VERSION ""

NS_ :

BS_:

BU_: GNSS_Receiver
VAL_TABLE_ TIM_AuthErrorCode 39 "LwAPossibleBitMismatch" 38 "AuthenticationAbortedDueToGeneralPeerError" 37 "AuthenticationAbortedByPeerDueToError" 36 "ChallengeDataCorrupt" 35 "InvalidChallengeLength" 34 "FunctionFacilityNotCertified" 33 "RequestNotAllowed" 32 "Reserved_0x20" 31 "AuthenticationTimeout" 30 "CertificateTypeInvalid" 29 "DeviceCertificateRevoked" 28 "ManufacturerSeriesCertificateRevoked" 27 "ManufacturerCertificateRevoked" 26 "LabCertificateRevoked" 25 "RootCertificateRevoked" 24 "CertificateTypeMismatch" 23 "CertificateChainInvalid" 22 "ECU_CCID_Mismatch" 21 "NAME_Mismatch" 20 "ECC_PublicKeyValidationFailed" 19 "UnexpectedRestartAuthenticationBitSet" 18 "AuthenticationStatusInvalid" 17 "AuthenticationTypeNotSupported" 16 "AuthenticationStatusLost" 15 "DeviceCertificateDataCorrupt" 14 "ManufacturerSeriesCertificateDataCorrupt" 13 "ManufacturerCertificateDataCorrupt" 12 "TestLabCertificateDataCorrupt" 11 "RootCertificateDataCorrupt" 10 "InternalError" 9 "ChallengesDontMatch" 8 "DeviceCertificateSignatureInvalid" 7 "ManufacturerSeriesCertificateSignatureInvalid" 6 "ManufacturerCertificateSignatureInvalid" 5 "LabCertificateSignatureInvalid" 4 "RootCertificateSignatureInvalid" 3 "NotAuthenticationServerOrClient" 2 "CertificateFormatNotSupported" 1 "ParticipantBusy" 0 "NoError" ;
VAL_TABLE_ TIM_CertificateType 255 "NotAvailable" 6 "CRLCertificate" 5 "CRLSigningCertificate" 4 "DeviceCertificate" 3 "ManufacturerSeriesCertificate" 2 "ManufacturerCertificate" 1 "TestlabCertificate" 0 "AEFRootCertificate" ;
VAL_TABLE_ NetworkInterconnUnitParametrics 16 "NetworkInterconnectionUnitType" 15 "NumberOfPorts" 14 "UptimeSinceLastPowerOnReset " 13 "AverageNumOfMsgsFilteredPerSec" 12 "AverageNumOfMsgsForwardedPerSec" 11 "AverageNumOfMsgsReceivedPerSec" 10 "NumOfMsgsWithExcessTransitDelayTime " 9 "NumOfMsgsLostDueToBufferOverflow " 8 "AverageTransitDelayTime" 7 "MaxTransitDelayTime" 6 "MaxNumOfMsgsFilteredPerSec" 5 "MaxNumOfMsgsForwardedPerSec" 4 "MaxNumOfMsgsReceivedPerSec" 3 "NumberOfFilterDatabaseEntries" 2 "MaxFilterDatabaseSize" 1 "BufferSize" 0 "RequestAllParameters" ;
VAL_TABLE_ FMI 0 "Above normal (most severe)" 1 "Below normal (most severe)" 2 "Data erratic" 3 "Voltage above normal" 4 "Voltage below normal" 5 "Current below normal" 6 "Current above normal" 7 "Mechanical system not responding" 8 "Abnormal frequency" 9 "Abnormal update rate" 10 "Abnormal rate of change" 11 "Root cause not known" 12 "Bad intelligent device" 13 "Out of calibration" 14 "Special intstructions" 15 "Above normal (least severe)" 16 "Above normal (moderately severe)" 17 "Below normal (least severe)" 18 "Below normal (moderately severe)" 19 "Received network data in error" 31 "Condition exists" 20 "Data drifted high" 21 "Data drifted low" ;

BO_ 3221225472 VECTOR__INDEPENDENT_SIG_MSG: 0 Vector__XXX
 SG_ ClientAuthenticationSubStatus : 0|8@1- (1,0) [0|255] "" Vector__XXX
 SG_ ServerAuthenticationSubStatus : 0|8@1- (1,0) [0|255] "" Vector__XXX

BO_ 2566845438 VP1: 8 Vector__XXX
 SG_ Longitude : 32|32@1+ (1E-07,-210) [-210|211.1081215] "deg" Vector__XXX
 SG_ Latitude : 0|32@1+ (1E-07,-210) [-210|211.1081215] "deg" Vector__XXX

BO_ 2565537534 RQST: 3 Vector__XXX
 SG_ ParameterGroupNumber : 0|24@1+ (1,0) [0|16777215] "" Vector__XXX

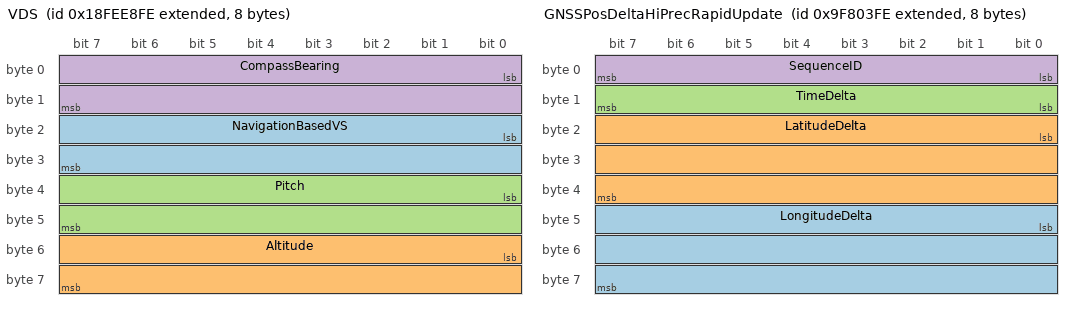
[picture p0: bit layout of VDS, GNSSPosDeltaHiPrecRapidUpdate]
BO_ 2566842622 VDS: 8 Vector__XXX
 SG_ NavigationBasedVS : 16|16@1+ (0.00390625,0) [0|250.99609375] "km/h" Vector__XXX
 SG_ Altitude : 48|16@1+ (0.125,-2500) [-2500|5531.875] "m" Vector__XXX
 SG_ Pitch : 32|16@1+ (0.0078125,-200) [-200|301.9921875] "deg" Vector__XXX
 SG_ CompassBearing : 0|16@1+ (0.0078125,0) [0|501.9921875] "deg" Vector__XXX

BO_ 2314732542 GNSSPosDeltaHiPrecRapidUpdate: 8 Vector__XXX
 SG_ LongitudeDelta : 40|24@1- (10,0) [0|0] "µsec" Vector__XXX
 SG_ LatitudeDelta : 16|24@1- (10,0) [0|0] "µsec" Vector__XXX
 SG_ TimeDelta : 8|8@1+ (5,0) [0|0] "ms" Vector__XXX
 SG_ SequenceID : 0|8@1+ (1,0) [0|0] "" Vector__XXX

BO_ 2314732030 GNSSPositionRapidUpdate: 8 Vector__XXX
 SG_ Longitude : 32|32@1- (1E-07,0) [-180|180] "deg" Vector__XXX
 SG_ Latitude : 0|32@1- (1E-07,0) [-90|90] "deg" Vector__XXX

BO_ 2381841918 GNSSPositionData: 47 Vector__XXX
 SG_ Reserved : 258|6@1+ (1,0) [0|0] "" Vector__XXX
 SG_ RefrenceStationType5 : 472|4@1+ (1,0) [0|15] "" Vector__XXX
 SG_ ReferenceStationID5 : 476|12@1+ (1,0) [0|4095] "" Vector__XXX
 SG_ AgeOfDGNSSCorrections5 : 488|16@1+ (0.01,0) [0|655.32] "sec" Vector__XXX
 SG_ RefrenceStationType4 : 440|4@1+ (1,0) [0|15] "" Vector__XXX
 SG_ ReferenceStationID4 : 444|12@1+ (1,0) [0|4095] "" Vector__XXX
 SG_ AgeOfDGNSSCorrections4 : 456|16@1+ (0.01,0) [0|655.32] "sec" Vector__XXX
 SG_ RefrenceStationType3 : 408|4@1+ (1,0) [0|15] "" Vector__XXX
 SG_ ReferenceStationID3 : 412|12@1+ (1,0) [0|4095] "" Vector__XXX
 SG_ AgeOfDGNSSCorrections3 : 424|16@1+ (0.01,0) [0|655.32] "sec" Vector__XXX
 SG_ RefrenceStationType2 : 376|4@1+ (1,0) [0|15] "" Vector__XXX
 SG_ ReferenceStationID2 : 380|12@1+ (1,0) [0|4095] "" Vector__XXX
 SG_ AgeOfDGNSSCorrections2 : 392|16@1+ (0.01,0) [0|655.32] "sec" Vector__XXX
 SG_ AgeOfDGNSSCorrections1 : 360|16@1+ (0.01,0) [0|655.32] "sec" Vector__XXX
 SG_ ReferenceStationID1 : 348|12@1+ (1,0) [0|4095] "" Vector__XXX
 SG_ RefrenceStationType1 : 344|4@1+ (1,0) [0|15] "" Vector__XXX
 SG_ NumberOfReferenceStations : 336|8@1+ (1,0) [0|252] "" Vector__XXX
 SG_ GeoidalSeparation : 304|32@1- (0.01,0) [-21470000|21470000] "m" Vector__XXX
 SG_ PDOP : 288|16@1- (0.01,0) [-327.64|327.64] "" Vector__XXX
 SG_ HDOP : 272|16@1- (0.01,0) [-327.64|327.64] "" Vector__XXX
 SG_ NumberOfSVs : 264|8@1+ (1,0) [0|252] "" Vector__XXX
 SG_ GNSSIntegrity : 256|2@1+ (1,0) [0|3] "" Vector__XXX
 SG_ GNSSMethod : 252|4@1+ (1,0) [0|15] "" Vector__XXX
 SG_ TypeOfSystem : 248|4@1+ (1,0) [0|4] "" Vector__XXX
 SG_ Altitude : 184|64@1- (1E-06,0) [-9223372036854.78|9223372036854.78] "m" Vector__XXX
 SG_ Longitude : 120|64@1- (1E-16,0) [-180|180] "deg" Vector__XXX
 SG_ Latitude : 56|64@1- (1E-16,0) [-90|90] "deg" Vector__XXX
 SG_ PositionTime : 24|32@1+ (0.0001,0) [0|86401] "s" Vector__XXX
 SG_ PositionDate : 8|16@1+ (1,0) [0|65532] "day" Vector__XXX
 SG_ SequenceID : 0|8@1+ (1,0) [0|255] "" Vector__XXX

BO_ 2565799678 AC: 8 GNSS_Receiver
 SG_ ReservedBit : 48|1@1+ (1,0) [0|0] "" Vector__XXX
 SG_ ArbitraryAddressCapable : 63|1@1+ (1,0) [0|1] "" Vector__XXX
 SG_ IndustryGroup M : 60|3@1+ (1,0) [0|7] "" Vector__XXX
 SG_ VehicleSystemInstance : 56|4@1+ (1,0) [0|15] "" Vector__XXX
 SG_ VehicleSystem m0 : 49|7@1+ (1,0) [0|127] "" Vector__XXX
 SG_ VehicleSystem5 m5 : 49|7@1+ (1,0) [0|127] "" Vector__XXX
 SG_ VehicleSystem4 m4 : 49|7@1+ (1,0) [0|127] "" Vector__XXX
 SG_ VehicleSystem3 m3 : 49|7@1+ (1,0) [0|127] "" Vector__XXX
 SG_ VehicleSystem2 m2 : 49|7@1+ (1,0) [0|127] "" Vector__XXX
 SG_ VehicleSystem1 m1 : 49|7@1+ (1,0) [0|127] "" Vector__XXX
 SG_ Function : 40|8@1+ (1,0) [0|255] "" Vector__XXX
 SG_ FunctionInstance : 35|5@1+ (1,0) [0|31] "" Vector__XXX
 SG_ ECUInstance : 32|3@1+ (1,0) [0|7] "" Vector__XXX
 SG_ ManufacturerCode : 21|11@1+ (1,0) [0|2047] "" Vector__XXX
 SG_ IdentityNumber : 0|21@1+ (1,0) [0|2097152] "" Vector__XXX

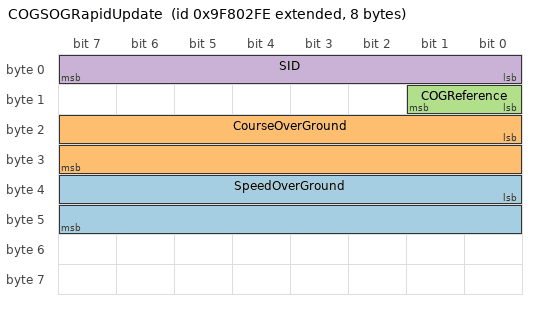
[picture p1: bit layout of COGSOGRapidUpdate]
BO_ 2314732286 COGSOGRapidUpdate: 8 Vector__XXX
 SG_ SpeedOverGround : 32|16@1+ (0.01,0) [0|655.32] "m/s" Vector__XXX
 SG_ CourseOverGround : 16|16@1+ (0.0001,0) [0|6.28318] "rad" Vector__XXX
 SG_ COGReference : 8|2@1+ (1,0) [0|3] "" Vector__XXX
 SG_ SID : 0|8@1+ (1,0) [0|252] "" Vector__XXX

CM_ BO_ 3221225472 "This is a message for not used signals, created by Vector CANdb++ DBC OLE DB Provider.";
CM_ SG_ 3221225472 ClientAuthenticationSubStatus "Sub-status of message Auth_ClientAuthenticationStatus (not mapped to AUTH21 because signals for every bit are used)";
CM_ SG_ 3221225472 ServerAuthenticationSubStatus "Sub-status of message Auth_ServerAuthenticationStatus (not mapped to AUTH12 because signals for every bit are used)";
CM_ BO_ 2566845438 "Vehicle Position 1";
CM_ SG_ 2566845438 Longitude "Longitude position of the vehicle.

Negative values are West and positive value are East.";
CM_ SG_ 2566845438 Latitude "Latitude position of the vehicle.

Negative values are South and positive values are North.";
CM_ BO_ 2565537534 "Request";
CM_ SG_ 2565537534 ParameterGroupNumber "PGN which is requested by the Request message";
CM_ BO_ 2566842622 "Vehicle Direction/Speed";
CM_ SG_ 2566842622 NavigationBasedVS "Speed of the vehicle as calculated from a device such as a Global Positioning System (GPS).";
CM_ SG_ 2566842622 Altitude "Altitude of the vehicle referenced to sea level at standard atmospheric pressure and temperature.";
CM_ SG_ 2566842622 Pitch "Pitch (rotation about the y-axis) of the vehicle as calculated by the navigation device(s).  The pitch angle for an angle of ascent is reported with a positive value. This parameter is defined according to a Z-Down axis system and the sign of the ...";
CM_ SG_ 2566842622 CompassBearing "Present compass bearing of vehicle.";
CM_ BO_ 2314732542 "This PGN is intended for applications where very high precision and very fast update rates are needed for position data 
and only has meaning when it is associated (via the Sequence ID field) with another PGN.";
CM_ SG_ 2314732542 SequenceID "An upward counting number used to tie related information together between different PGNs.";
CM_ BO_ 2314732030 "This PGN provides latitude and longitude referenced to WGS84";
CM_ BO_ 2381841918 "This PGN conveys a comprehensive set of Global Navigation Satellite System (GNSS) parameters, including position 
information
";
CM_ SG_ 2381841918 ReferenceStationID5 "Reference Station ID";
CM_ SG_ 2381841918 AgeOfDGNSSCorrections5 "Age of Differential corrections";
CM_ SG_ 2381841918 ReferenceStationID4 "Reference Station ID";
CM_ SG_ 2381841918 AgeOfDGNSSCorrections4 "Age of Differential corrections";
CM_ SG_ 2381841918 ReferenceStationID3 "Reference Station ID";
CM_ SG_ 2381841918 AgeOfDGNSSCorrections3 "Age of Differential corrections";
CM_ SG_ 2381841918 ReferenceStationID2 "Reference Station ID";
CM_ SG_ 2381841918 AgeOfDGNSSCorrections2 "Age of Differential corrections";
CM_ SG_ 2381841918 AgeOfDGNSSCorrections1 "Age of Differential corrections";
CM_ SG_ 2381841918 ReferenceStationID1 "Reference Station ID";
CM_ SG_ 2381841918 NumberOfReferenceStations "Numeric count, event counter, sequence counter";
CM_ SG_ 2381841918 GeoidalSeparation "The difference between the earth ellipsoid and mean-sea-level (geoid) defined by the reference datum used in the position solution ' -' = mean-sea-level below ellipsoid
";
CM_ SG_ 2381841918 PDOP "Dilution of Precision (DOP) indicates the contribution of satellite configuration geometry to positioning error
";
CM_ SG_ 2381841918 HDOP "Dilution of Precision (DOP) indicates the contribution of satellite configuration geometry to positioning error
";
CM_ SG_ 2381841918 NumberOfSVs "Numeric count, event counter, sequence counter";
CM_ SG_ 2381841918 Altitude "Altitude referenced to WGS-84";
CM_ SG_ 2381841918 Longitude "Longitude referenced to WGS-84";
CM_ SG_ 2381841918 Latitude "Latitude referenced to WGS-84";
CM_ SG_ 2381841918 PositionTime "24 hour clock, 0 =  midnight,  time is in UTC";
CM_ SG_ 2381841918 PositionDate "Days since January 1, 1970,  Date is relative to UTC Time";
CM_ SG_ 2381841918 SequenceID "An upward counting number used to tie related information together between different PGNs.
";
CM_ BO_ 2565799678 "Address Claimed";
CM_ SG_ 2565799678 ReservedBit "The reserved bit shall be set to zero.";
CM_ BO_ 2314732286 "This PGN is a single frame PGN that provides Course Over Ground(COG)and Speed Over Ground(SOG).

Being a single frame Msg,as opposed to other PGNs that include COG and SOG and are defined as multi-packet,this PGN lends itself to being transmitted more f";
CM_ SG_ 2314732286 CourseOverGround "The direction of the path over ground actually followed by a vessel.";
CM_ SG_ 2314732286 COGReference "0 = True, 
1 = Magnetic, 
2 = Error, 
3 = Null";
CM_ SG_ 2314732286 SID "An upward counting number used to tie related information together between different PGNs.For example,SID would be used to tie together COG,SOG and RAIM values to a given Pos.255=no valid Pos fix to tie it to.Range 0 to 250 for valid Pos fixes.";
BA_DEF_ BO_  "TpJ1939VarDlc" ENUM  "No","Yes";
BA_DEF_ BO_  "FsJ1939NeedsSHM" ENUM  "No","Yes";
BA_DEF_ BO_  "FsJ1939Delay" INT 0 1000;
BA_DEF_ BO_  "FsJ1939UseCrcAndCounter" STRING ;
BA_DEF_ BO_  "J1939PgAppearanceOnBus" ENUM  "Default","CAN_Extended","CANFD_Extended";
BA_DEF_ BO_  "J1939CPgTF" INT 0 7;
BA_DEF_ BO_  "J1939CPgTOS" INT 0 7;
BA_DEF_ BO_  "J1939CPgSendTimeout" INT -1 3600000;
BA_DEF_ BO_  "J1939FdTpADS" INT 0 52;
BA_DEF_ BO_  "J1939FdTpADT" INT 0 255;
BA_DEF_ BU_  "J1939MultiPgBroadcastType" ENUM  "FBFF","FEFF";
BA_DEF_ BU_  "J1939MultiPgSizeThreshold" INT 0 64;
BA_DEF_ BU_  "J1939MultiPgSendTimeout" INT 0 3600000;
BA_DEF_ SG_  "SAEDocument" STRING ;
BA_DEF_ SG_  "GenSigEVName" STRING ;
BA_DEF_ BO_  "SAE_Document" STRING ;
BA_DEF_  "ISO11783_11_SpecVersion" STRING ;
BA_DEF_  "ISO11783_7_SpecVersion" STRING ;
BA_DEF_  "ISO11783_6_SpecVersion" STRING ;
BA_DEF_ SG_  "DDI" INT 0 65535;
BA_DEF_ BO_  "SingleFrame" INT 0 1;
BA_DEF_ BU_  "NodeLayerModules" STRING ;
BA_DEF_  "ProtocolType" STRING ;
BA_DEF_  "BusType" STRING ;
BA_DEF_  "ISO11783_TIM_SpecVersion" STRING ;
BA_DEF_ BU_  "NmStationAddress" INT 0 254;
BA_DEF_ BU_  "NmJ1939AAC" INT 0 1;
BA_DEF_ BU_  "NmJ1939Function" INT 0 255;
BA_DEF_ BU_  "NmJ1939ManufacturerCode" INT 0 2047;
BA_DEF_ BO_  "VFrameFormat" ENUM  "StandardCAN","ExtendedCAN","reserved","J1939PG","vector_leerstring";
BA_DEF_ BO_  "GenMsgSendType" ENUM  "cyclic","reserved","cyclicIfActive","reserved","reserved","reserved","reserved","reserved","noMsgSendType","vector_leerstring";
BA_DEF_ BO_  "GenMsgCycleTime" INT 0 3600000;
BA_DEF_ BO_  "GenMsgRequestable" INT 0 1;
BA_DEF_ BO_  "GenMsgNrOfRepetition" INT 0 1000000;
BA_DEF_ BO_  "GenMsgCycleTimeFast" INT 0 3600000;
BA_DEF_ SG_  "GenSigInactiveValue" INT 0 0;
BA_DEF_ BO_  "GenMsgFastOnStart" INT 0 100000;
BA_DEF_ BO_  "GenMsgStartDelayTime" INT 0 100000;
BA_DEF_ BO_  "GenMsgILSupport" ENUM  "No","Yes";
BA_DEF_ BO_  "GenMsgDelayTime" INT 0 1000;
BA_DEF_ SG_  "SPN" INT 0 524287;
BA_DEF_  "DatabaseVersion" STRING ;
BA_DEF_ SG_  "GenSigSendType" ENUM  "Cyclic","OnWrite","OnWriteWithRepetition","OnChange","OnChangeWithRepetition","IfActive","IfActiveWithRepetition","NoSigSendType";
BA_DEF_ SG_  "SigType" ENUM  "Default","Range","RangeSigned","ASCII","Discrete","Control","ReferencePGN","DTC","StringDelimiter","StringLength","StringLengthControl";
BA_DEF_  "ISO11783_12_SpecVersion" STRING ;
BA_DEF_  "ISO11783_13_SpecVersion" STRING ;
BA_DEF_ SG_  "GenSigStartValue" INT -2147483648 2147483647;
BA_DEF_ BU_  "ISO11783IOPVersion" ENUM  "0","1","2","3","4","5","6";
BA_DEF_ BU_  "ISO11783PDDVersion" ENUM  "0","1","2","3";
BA_DEF_ SG_  "GenSigILSupport" ENUM  "No","Yes";
BA_DEF_DEF_  "TpJ1939VarDlc" "No";
BA_DEF_DEF_  "FsJ1939NeedsSHM" "No";
BA_DEF_DEF_  "FsJ1939Delay" 0;
BA_DEF_DEF_  "FsJ1939UseCrcAndCounter" "";
BA_DEF_DEF_  "J1939PgAppearanceOnBus" "Default";
BA_DEF_DEF_  "J1939CPgTF" 0;
BA_DEF_DEF_  "J1939CPgTOS" 2;
BA_DEF_DEF_  "J1939CPgSendTimeout" -1;
BA_DEF_DEF_  "J1939FdTpADS" 0;
BA_DEF_DEF_  "J1939FdTpADT" 0;
BA_DEF_DEF_  "J1939MultiPgBroadcastType" "FBFF";
BA_DEF_DEF_  "J1939MultiPgSizeThreshold" 56;
BA_DEF_DEF_  "J1939MultiPgSendTimeout" 2;
BA_DEF_DEF_  "SAEDocument" "";
BA_DEF_DEF_  "GenSigEVName" "Env@Nodename_@Signame";
BA_DEF_DEF_  "SAE_Document" "";
BA_DEF_DEF_  "ISO11783_11_SpecVersion" "";
BA_DEF_DEF_  "ISO11783_7_SpecVersion" "";
BA_DEF_DEF_  "ISO11783_6_SpecVersion" "";
BA_DEF_DEF_  "DDI" 0;
BA_DEF_DEF_  "SingleFrame" 1;
BA_DEF_DEF_  "NodeLayerModules" "GNSS_NL.vmodule";
BA_DEF_DEF_  "ProtocolType" "";
BA_DEF_DEF_  "BusType" "";
BA_DEF_DEF_  "ISO11783_TIM_SpecVersion" "";
BA_DEF_DEF_  "NmStationAddress" 254;
BA_DEF_DEF_  "NmJ1939AAC" 0;
BA_DEF_DEF_  "NmJ1939Function" 0;
BA_DEF_DEF_  "NmJ1939ManufacturerCode" 0;
BA_DEF_DEF_  "VFrameFormat" "J1939PG";
BA_DEF_DEF_  "GenMsgSendType" "noMsgSendType";
BA_DEF_DEF_  "GenMsgCycleTime" 0;
BA_DEF_DEF_  "GenMsgRequestable" 1;
BA_DEF_DEF_  "GenMsgNrOfRepetition" 0;
BA_DEF_DEF_  "GenMsgCycleTimeFast" 0;
BA_DEF_DEF_  "GenSigInactiveValue" 0;
BA_DEF_DEF_  "GenMsgFastOnStart" 0;
BA_DEF_DEF_  "GenMsgStartDelayTime" 0;
BA_DEF_DEF_  "GenMsgILSupport" "Yes";
BA_DEF_DEF_  "GenMsgDelayTime" 0;
BA_DEF_DEF_  "SPN" 0;
BA_DEF_DEF_  "DatabaseVersion" "";
BA_DEF_DEF_  "GenSigSendType" "NoSigSendType";
BA_DEF_DEF_  "SigType" "Default";
BA_DEF_DEF_  "ISO11783_12_SpecVersion" "";
BA_DEF_DEF_  "ISO11783_13_SpecVersion" "";
BA_DEF_DEF_  "GenSigStartValue" 0;
BA_DEF_DEF_  "ISO11783IOPVersion" "5";
BA_DEF_DEF_  "ISO11783PDDVersion" "3";
BA_DEF_DEF_  "GenSigILSupport" "Yes";
BA_ "ISO11783_TIM_SpecVersion" "AEF 023 DIG 0_07 ISOBUS - ISOBUS Automation Principles";
BA_ "ISO11783_13_SpecVersion" "2010-01-29 2007 With Amendments ";
BA_ "BusType" "CAN";
BA_ "ISO11783_11_SpecVersion" "2007-04-01 IS";
BA_ "ISO11783_7_SpecVersion" "2009-01-29 FDIS";
BA_ "ISO11783_6_SpecVersion" "2010-05-11 FDIS";
BA_ "ProtocolType" "ISO11783";
BA_ "DatabaseVersion" "7.5 SP2";
BA_ "ISO11783_12_SpecVersion" "2013-01-29 IS (ISO/TC 23/SC 19)";
BA_ "NmStationAddress" BU_ GNSS_Receiver 10;
BA_ "NodeLayerModules" BU_ GNSS_Receiver "ISO11783_GNSS_IL.dll";
BA_ "NmJ1939AAC" BU_ GNSS_Receiver 1;
BA_ "NmJ1939Function" BU_ GNSS_Receiver 23;
BA_ "NmJ1939ManufacturerCode" BU_ GNSS_Receiver 1861;
BA_ "GenMsgCycleTime" BO_ 2566845438 1000;
BA_ "GenMsgCycleTime" BO_ 2566842622 1000;
BA_ "SAE_Document" BO_ 2566842622 "J1939-71";
BA_ "GenMsgSendType" BO_ 2314732542 0;
BA_ "GenMsgCycleTime" BO_ 2314732542 100;
BA_ "GenMsgCycleTime" BO_ 2314732030 100;
BA_ "GenMsgSendType" BO_ 2314732030 8.51951780093012E-317;
BA_ "SingleFrame" BO_ 2381841918 0;
BA_ "GenMsgCycleTime" BO_ 2381841918 1000;
BA_ "GenMsgSendType" BO_ 2381841918 8.52390115134002E-317;
BA_ "GenMsgCycleTime" BO_ 2314732286 250;
BA_ "GenMsgSendType" BO_ 2314732286 0;
BA_ "SPN" SG_ 3221225472 ClientAuthenticationSubStatus 13223;
BA_ "SPN" SG_ 3221225472 ServerAuthenticationSubStatus 13223;
BA_ "SPN" SG_ 2566845438 Longitude 585;
BA_ "SPN" SG_ 2566845438 Latitude 584;
BA_ "SigType" SG_ 2565537534 ParameterGroupNumber 6;
BA_ "SPN" SG_ 2565537534 ParameterGroupNumber 2574;
BA_ "SPN" SG_ 2566842622 NavigationBasedVS 517;
BA_ "SAEDocument" SG_ 2566842622 Altitude "J1939-71";
BA_ "SPN" SG_ 2566842622 Altitude 580;
BA_ "SigType" SG_ 2566842622 Altitude 1;
BA_ "SAEDocument" SG_ 2566842622 Pitch "J1939-71";
BA_ "SPN" SG_ 2566842622 Pitch 583;
BA_ "SigType" SG_ 2566842622 Pitch 1;
BA_ "SAEDocument" SG_ 2566842622 CompassBearing "J1939-71";
BA_ "SPN" SG_ 2566842622 CompassBearing 165;
BA_ "SigType" SG_ 2566842622 CompassBearing 1;
BA_ "GenSigStartValue" SG_ 2381841918 Reserved 63;
BA_ "SigType" SG_ 2381841918 ReferenceStationID5 1;
BA_ "SigType" SG_ 2381841918 AgeOfDGNSSCorrections5 1;
BA_ "SigType" SG_ 2381841918 ReferenceStationID4 1;
BA_ "SigType" SG_ 2381841918 AgeOfDGNSSCorrections4 1;
BA_ "SigType" SG_ 2381841918 ReferenceStationID3 1;
BA_ "SigType" SG_ 2381841918 AgeOfDGNSSCorrections3 1;
BA_ "SigType" SG_ 2381841918 ReferenceStationID2 1;
BA_ "SigType" SG_ 2381841918 AgeOfDGNSSCorrections2 1;
BA_ "SigType" SG_ 2381841918 AgeOfDGNSSCorrections1 1;
BA_ "SigType" SG_ 2381841918 ReferenceStationID1 1;
BA_ "SigType" SG_ 2381841918 NumberOfReferenceStations 1;
BA_ "SigType" SG_ 2381841918 GeoidalSeparation 2;
BA_ "SigType" SG_ 2381841918 PDOP 2;
BA_ "SigType" SG_ 2381841918 HDOP 2;
BA_ "SigType" SG_ 2381841918 NumberOfSVs 1;
BA_ "SigType" SG_ 2381841918 GNSSIntegrity 4;
BA_ "SigType" SG_ 2381841918 PositionTime 1;
BA_ "SigType" SG_ 2381841918 PositionDate 1;
BA_ "SigType" SG_ 2381841918 SequenceID 1;
BA_ "SPN" SG_ 2565799678 ArbitraryAddressCapable 2844;
BA_ "SPN" SG_ 2565799678 IndustryGroup 2846;
BA_ "SPN" SG_ 2565799678 VehicleSystemInstance 2843;
BA_ "SPN" SG_ 2565799678 Function 2841;
BA_ "SPN" SG_ 2565799678 FunctionInstance 2839;
BA_ "SPN" SG_ 2565799678 ECUInstance 2840;
BA_ "SPN" SG_ 2565799678 ManufacturerCode 2838;
BA_ "SigType" SG_ 2565799678 ManufacturerCode 1;
BA_ "SPN" SG_ 2565799678 IdentityNumber 2837;
BA_ "SigType" SG_ 2314732286 SpeedOverGround 1;
BA_ "SigType" SG_ 2314732286 CourseOverGround 1;
BA_ "SigType" SG_ 2314732286 COGReference 4;
BA_ "SigType" SG_ 2314732286 SID 1;
VAL_ 2381841918 RefrenceStationType5 14 "Error" 1 "GLONASS" 0 "GPS" ;
VAL_ 2381841918 RefrenceStationType4 14 "Error" 1 "GLONASS" 0 "GPS" ;
VAL_ 2381841918 RefrenceStationType3 14 "Error" 1 "GLONASS" 0 "GPS" ;
VAL_ 2381841918 RefrenceStationType2 14 "Error" 1 "GLONASS" 0 "GPS" ;
VAL_ 2381841918 RefrenceStationType1 14 "Error" 1 "GLONASS" 0 "GPS" ;
VAL_ 2381841918 GNSSIntegrity 3 "Unsafe" 2 "Caution" 1 "Safe" 0 "No integrity checking" ;
VAL_ 2381841918 GNSSMethod 14 "Error" 8 "Simulate mode" 7 "Manual input" 6 "Estimated (DR) mode" 5 "RTK float" 4 "RTK fixed integer" 3 "Precise GNSS" 2 "DGNSS fix" 1 "GNSS fix" 0 "no GPS" ;
VAL_ 2381841918 TypeOfSystem 4 "GPS and SBAS and GLONASS" 3 "GPS and SBAS(WAAS)" 2 "GPS and GLONASS" 1 "GLONASS" 0 "GPS" ;
VAL_ 2565799678 IndustryGroup 7 "Reserved for SAE" 5 "IndustrialProcessCtrlStationary" 4 "Marine" 3 "Construction" 2 "AgriculturalAndForestry" 1 "On-Highway" 0 "Global" ;
VAL_ 2565799678 VehicleSystem 127 "Not Available" 0 "NonSpecificSystem" ;
VAL_ 2565799678 VehicleSystem5 0 "Ind. Process Control Stationary" 127 "Not Available" ;
VAL_ 2565799678 VehicleSystem4 0 "NonSpecificSystem" 127 "Not Available" 10 "System Tools" 20 "Safety Systems" 25 "Inter/Intranetwork Device" 30 "Electrical Distribution" 40 "Steering and Control Surfaces" 50 "Propulsion" 60 "Navigation" 70 "Communications" 80 "Instrumentation/General Systems (deprecate)" 90 "Internal Environment" 100 "Deck, Cargo and Fishing Equipment" 35 "Electrical Generation" 75 "Sensor Communication Interface" 85 "External Environment" 120 "Display" 125 "Entertainment" ;
VAL_ 2565799678 VehicleSystem3 0 "NonSpecificSystem" 127 "Not Available" 1 "Skid Steer Loader" 2 "Articulated Dump Truck" 3 "Backhoe" 4 "Crawler" 5 "Excavator" 6 "Forklift" 7 "Four Wheel Drive Loader" 8 "Grader" ;
VAL_ 2565799678 VehicleSystem2 0 "NonSpecificSystem" 127 "Not Available" 1 "Tractor" 2 "Tillage" 3 "Secondary Tillage" 4 "Planters/Seeders" 5 "Fertilizers" 6 "Sprayers" 7 "Harvesters" 8 "Root Harvesters" 9 "Forage" 10 "Irrigation" 11 "Transport/Trailer" 12 "Farm Yard Operations" 13 "Powered Auxiliary Device" 14 "Special Crops" 15 "Earth Work" 16 "Skidder" 17 "Sensor Systems" 19 "Timber Harvesters" 20 "Forwarders" 21 "Timber loaders" 22 "Timber Processing Machines" 23 "Mulchers" 24 "Utility Vehicles" 25 "Slurry Applicators" ;
VAL_ 2565799678 VehicleSystem1 0 "NonSpecificSystem" 127 "Not Available" 1 "Tractor" 2 "Trailer" ;
VAL_ 2565799678 Function 142 "TIMServer" 43 "Transmission Display" 44 "Exhaust Emission Control" 45 "Vehicle Dynamic Stability Control" 46 "Oil Sensor Unit" 47 "Information System Controller" 48 "Ramp Control" 49 "Clutch/Converter Control" 50 "Auxiliary Heater" 51 "Forward-Looking Collision Warning System" 52 "Chassis Controller" 53 "Alternator/Charging System" 54 "Communications Unit, Cellular" 55 "Communications Unit, Satellite" 56 "Communications Unit, Radio" 57 "Steering Column Unit" 58 "Fan Drive Control" 59 "Starter" 60 "Cab Display" 61 "File Server/Printer" 62 "On-Board Diagnostic Unit" 63 "Engine Valve Controller" 64 "Endurance Braking" 65 "Gas Flow Measurement" 66 "I/O Controller" 67 "Electrical System Controller" 68 "Aftertreatment system gas measurement" 69 "Engine Emission Aftertreatement System" 70 "Auxiliary Regeneration Device" 71 "Transfer Case Control" 72 "Coolant Valve Controller" 73 "Rollover Detection Control" 74 "Lubrication System" 75 "Supplemental Fan" 76 "Temperature Sensor" 77 "Fuel Properties Sensor" 78 "Fire Suppression System" 79 "Power Systems Manager" 80 "Electric Powertrain" 81 "Hydraulic Powertrain" 82 "File Server" 83 "Printer" 84 "Start Aid Device" 85 "Engine Injection Control Module" 86 "Reserved" 87 "Reserved" 88 "Reserved" 89 "Reserved" 90 "Reserved" 91 "Reserved" 92 "Reserved" 93 "Reserved" 94 "Reserved" 95 "Reserved" 96 "Reserved" 97 "Reserved" 98 "Reserved" 99 "Reserved" 100 "Reserved" 0 "Engine" 1 "Auxiliary Power Unit (APU)" 2 "Electric Propulsion Control" 3 "Transmission" 4 "Battery Pack Monitor" 5 "Shift Control/Console" 6 "Power TakeOff - (Main or Rear)" 7 "Axle - Steering" 8 "Axle - Drive" 9 "Brakes - System Controller" 10 "Brakes - Steer Axle" 11 "Brakes - Drive Axle" 12 "Retarder - Engine" 13 "Retarder - Driveline" 14 "Cruise Control" 15 "Fuel System" 16 "Steering Controller" 17 "Suspension - Steer Axle" 18 "Suspension - Drive Axle" 19 "Instrument Cluster" 20 "Trip Recorder" 21 "Cab Climate Control" 22 "Aerodynamic Control" 23 "Vehicle Navigation" 24 "Vehicle Security" 25 "Network Interconnect ECU" 26 "Body Controller" 27 "Power TakeOff (Secondary or Front)" 28 "Off Vehicle Gateway" 29 "Virtual Terminal (in cab)" 30 "Management Computer" 31 "Propulsion Battery Charger" 32 "Headway Controller" 33 "System Monitor" 34 "Hydraulic Pump Controller" 35 "Suspension - System Controller" 36 "Pneumatic - System Controller" 37 "Cab Controller" 38 "Tire Pressure Control" 39 "Ignition Control Module" 40 "Seat Control" 41 "Lighting - Operator Controls" 42 "Water Pump Control" 101 "Reserved" 102 "Reserved" 103 "Reserved" 104 "Reserved" 105 "Reserved" 106 "Reserved" 107 "Reserved" 108 "Reserved" 109 "Reserved" 110 "Reserved" 111 "Reserved" 112 "Reserved" 113 "Reserved" 114 "Reserved" 115 "Reserved" 116 "Reserved" 117 "Reserved" 118 "Reserved" 119 "Reserved" 120 "Reserved" 121 "Reserved" 122 "Reserved" 123 "Reserved" 124 "Reserved" 125 "Reserved" 126 "Reserved" 127 "Reserved" 255 "Not Available" ;
VAL_ 2565799678 ManufacturerCode 1077 "Ymer Technology" 1076 "DOGA S.A." 1075 "Uniden America Corporation" 1074 "Kindhelm / Navigs Oy" 1073 "Manitou Equipment America LLC" 1072 "La Marche Manufacturing Company" 1071 "MACH SYSTEMS s.r.o." 1070 "Quick-teck Electronics Ltd" 1069 "Lithionics Battery LLC" 1068 "Zapi S.p.A." 1067 "Tecomec S.r.l." 1066 "Spot Zero Water" 1065 "CALYPSO Instruments" 1064 "Omnitech Robotics Inc." 1063 "SolSteer" 1062 "Marol Co Ltd" 1061 "Volvo Construction Equipment" 1060 "Scale-Tec" 1059 "Boatrax" 1058 "Bondioli & Pavesi SpA" 1057 "EquipmentShare" 1056 "Lithium Pros" 1055 "EXA Computing GmbH" 1054 "Schmotzer Hacktechnik GmbH & Co. KG" 1053 "Vetus Maxwell, Inc." 1052 "Pfreundt" 1051 "ProNav AS" 1050 "Spacenus GmbH" 1049 "S&S Cycle" 1048 "Agrivation UG" 1047 "Sonic Corporation" 1046 "Praxidyn" 1045 "CMR Group" 1044 "Xee" 1043 "Hyva" 1042 "engcon group" 1041 "EZ Lynk" 1040 "BPE Electronics Srl" 1039 "Liugong Dressta Machinery" 1038 "EMIT Technologies, Inc." 1037 "Dragonfly Energy Corp." 1036 "Bender GmbH & Co. KG" 1035 "Agres" 1034 "Siren Marine" 1033 "ECCO Safety Group" 1032 "SIMOL S.p.A." 1031 "Flintec UK Ltd." 1030 "Tume-Agri Oy" 1029 "The Marine Guardian LLC" 1028 "Autel Intelligent Technology Corp., Ltd" 1027 "Goldacres PTY LTD" 1026 "ZTR Control Systems, LLC" 1025 "eze System, Inc." 1024 "Inventus Power" 1023 "PEAK-System Technik GmbH" 1022 "ITC Inc" 1021 "Entratech Systems LLC" 1020 "Onyx Marine Automation s.r.l." 1019 "Codek Foundries" 1018 "Flex TTS" 1017 "Caldaro AB" 1016 "Röhren- und Pumpenwerk BAUER GmbH" 1015 "SECURITAG SAS" 1014 "Briri Maschinenbau GmbH" 1013 "Allochis E-Tec" 1012 "Rhodan Marine Systems of Florida LLC" 1011 "Soundmax Electronics Ltd" 1010 "Agricultural Industry Electronics Foundation e.V." 1009 "TouchTronics, Inc." 1008 "Lintest Systems LLC" 1007 "Maschinenfabrik Meyer-Lohne GmbH" 1006 "Proterra" 1005 "TSE Brakes, Inc." 1004 "Ultraflex SpA" 1003 "technotrans SE" 1002 "Kussmaul Electronics Co." 1001 "Cleral Inc." 1000 "Landmaschinen Wienhoff GmbH" 1569 "621 Technologies Inc." 999 "TerraTroniq B.V." 998 "Transcell Technology Inc" 997 "Xenta Systems Srl" 996 "Eniquest Pty Ltd" 995 "Circuitlink Pty Ltd." 994 "Morris Industries Ltd." 993 "Alelion Energy Systems AB" 992 "MarineIOT LLC" 991 "Deutronic Elektronik GmbH" 990 "SAMSUNG SDI Co., Ltd." 989 "Flux-Geräte GmbH" 988 "Voith Turbo" 987 "Baltic Car Equipment" 986 "AAMP Global" 985 "NLR, LLC" 984 "E-T-A Elektrotechnische Apparate GmbH" 983 "Dezwaef NV" 982 "Briggs & Stratton Corporation" 981 "Kobelt Manufacturing Co. Ltd" 980 "Gussi Italia S.R.L." 979 "McHale" 978 "Canfield Connector" 977 "Emerson Electric Co." 976 "Derive Systems, Inc." 975 "Siemens AG" 974 "Pico Technology Limited" 973 "Zasso GmbH" 972 "Axion AG" 971 "B+B Smartworx" 970 "Jaboni Power Products, LLC" 969 "Blue Sea Systems" 968 "Cox Powertrain Limited" 967 "Moteck Electric Corp." 966 "VisibleFarm" 965 "Ro-Sys Software" 964 "AgroVIR Kft" 963 "Thomason Jones Company, LLC" 962 "Timbolier Industries, Inc." 961 "POK SAS" 960 "Vemcon GmbH" 959 "Cascade Corporation" 958 "NHK MEC Corporation" 957 "Sierra Wireless Inc" 956 "Piher Sensors & Controls S.A." 955 "Hottinger Baldwin (Suzhou) Electronic Measurement Technology Co., Ltd." 954 "Setec Pty Ltd" 953 "Curtiss-Wright" 952 "Tan Delta Systems Ltd" 951 "Exor International S.p.A." 950 "RE:Lab s.r.l." 949 "Škoda Electric a.s." 948 "Donix" 947 "Gerd Bär GmbH" 946 "Hydac Tecnologia Ltda" 945 "Equalizer AG" 944 "ZONTISA Marine SL" 943 "FISCHER AG Präzisionspindeln" 942 "Vogelsang GmbH & Co. KG" 941 "Navya" 940 "Dometal Oy" 939 "Warn Industries, Inc." 938 "LEVEL Systems" 937 "Precision Circuits Inc" 936 "Hi-tech Millennium" 935 "Meels GmbH & Co. KG" 934 "Farmobile, Inc." 933 "Delta Mobile Systems, Inc." 932 "Discover Battery" 931 "Enertec Marine Ltd" 930 "Ecotronix Corp." 929 "Jl Marine Systems, Inc." 928 "EAO Automotive GmbH & Co. KG" 927 "Saicon" 926 "Buhler Industries Inc." 925 "GW Lisk Company" 924 "PAS Peschak Autonome Systeme GmbH" 923 "ELTEK S.p.A." 922 "Terberg Benschop B.V." 921 "ROPA Fahrzeug- und Maschinenbau GmbH" 920 "MTD Consumer Group Inc." 919 "Furrion LLC" 918 "AMW Machine Control, Inc" 917 "Sentinel d.o.o." 916 "Turck Inc." 915 "Dosificacion y sistemas electronicos S.L. (DSE)" 914 "ZETOR TRACTORS a.s." 913 "Toyota Motor Corporation" 912 "Steyr Motors GmbH" 911 "Nautic-On" 910 "Hermann Paus Maschinenfabrik GmbH" 909 "Marines Co., Ltd." 908 "Chonbuk National University Department of Electronics" 907 "strautmann" 906 "MOBA AG" 905 "ASA Electronics" 904 "Equipment Safety Systems Pty. Ltd. (EQSS)" 903 "InMotion" 902 "Bucher Hydraulics" 901 "Zivan Srl" 900 "OSB AG" 899 "Lippert Components, Inc" 898 "Josef Kotte Landtechnik GmbH & Co. KG" 897 "Dot Technology Corp." 896 "NextFour Solutions Ltd" 895 "Peloton Technology" 894 "Rhodan Marine Systems of Florida LLC" 893 "KlinkTechnics Ltd." 892 "Mectronx Corp" 891 "CarrierWeb" 890 "L3 Technologies, Inc." 889 "SANY America Inc" 888 "Carma Systems Inc" 887 "Hyperdrive Innovation Limited" 886 "Hitachi Zosen Corporation" 885 "SICK Stegmann GmbH" 884 "Sure Grip Controls Inc." 883 "Swift Navigation, Inc." 882 "BHTronik GmbH & Co. KG" 881 "Sovema" 880 "Revision Military" 879 "PG Trionic, Inc." 878 "FOTON" 877 "SICK ATech GmbH" 876 "SUCO Robert Scheuffele GmbH & Co. KG" 875 "Salvarani S.r.l." 874 "MTA S.p.A." 873 "Garnet Instruments Ltd." 872 "Kählig Antriebstechnik GmbH" 871 "Superior Tech Inc" 870 "Textron Fleet Management" 869 "Intercomp" 868 "Data Panel Corp" 867 "Skeleton Technologies" 866 "Netradyne, Inc." 865 "MyEasyFarm" 864 "Streamline Transportation Technologies Inc." 863 "SMAG" 862 "Prospec Electronics" 861 "Adel System S.r.l." 860 "Michelin" 859 "Valor" 858 "Littelfuse" 857 "Zoomlion Heavy Industry NA, Inc" 856 "FarmFacts GmbH" 855 "Toshiba Infrastructure Systems & Solutions Corporation" 854 "GEMAC Chemnitz GmbH" 853 "Teledyne RESON B.V." 852 "Velvac Inc" 851 "Novotechnik Messwertaufnehmer OHG" 850 "Geoprospectors GmbH" 849 "MTS Maschinentechnik Schrode AG" 848 "ningupex" 847 "Oceanvolt" 846 "L3 Magnet-Motor" 845 "GMB Güstrower Maschinenbau GmbH" 844 "FELL AS" 843 "Hendrickson Truck Commercial Vehicle Systems" 842 "DigiDevice Srl" 841 "Agra-GPS" 840 "E.S.T.E. Srl" 839 "Indexator Rotator Systems AB" 838 "Teamsurv Ltd" 837 "Famic Technologies Inc." 836 "Signature4" 835 "PetTrack Ltd." 834 "Pioneer Microsystems, Inc." 833 "Electrum Automation AB" 832 "Heizomat Gerätebau-Energiesysteme GmbH" 831 "DOK-ING Ltd." 830 "Ultra Motion LLC" 829 "Drov Technologies, Inc." 828 "AgriBrink Inc." 827 "INmatix Technology Group Ltd" 826 "Lewmar Marine Inc" 825 "BPW Hungária" 824 "Undheim Systems AS" 823 "ACEINNA, Inc (formerly MEMSIC, Inc)" 822 "Bren-Tronics, Inc." 821 "Thorsen Teknik A/S" 820 "DIaLOGIKa Gesellschaft fuer angewandte Informatik mbH" 819 "Preco Electronics" 818 "HGNSS" 817 "TE Connectivity Sensor Solutions" 816 "UniStrong" 815 "FLIR Systems, Inc." 814 "Kronotech Srl (formerly Soltec Soluzioni Tecnologiche Srl)" 813 "Thales Suisse SA" 812 "Torch Technologies" 811 "Blue Water Desalination" 810 "Dutch Power Company" 809 "HMS Industrial Networks AB" 808 "RIMEX Supply Ltd." 807 "Schneider-Electric" 806 "Charge Automotive Ltd" 805 "Gundersen & Løken AS" 804 "ASA Electronics" 803 "Gill Sensors & Controls Limited" 802 "SPBI (Bj Technologie)" 801 "LOR Manufacturing Company Inc." 800 "Delta-Q Technologies" 799 "Stillwater Designs and Audio, Inc. - KICKER" 798 "Lumishore Ltd" 797 "Tides Marine" 796 "Canadian Automotive Industries Ltd" 795 "Broyda Enterprises Pty Ltd" 794 "Shihlin Electric & Engineering Corporation" 793 "James Fisher Prolec" 792 "Kostal Mexicana" 791 "AUTEC" 790 "VACALL" 789 "GRADALL" 788 "MoTeC Pty Ltd" 787 "Abertax Technologies Limited" 1863 "Thomas G. Faria Co." 1862 "Sanshin" 1861 "Vector North America" 1860 "MMP" 1859 "Kvasar AB" 1858 "Litton" 1857 "Simrad" 1856 "Trimble" 1855 "Furuno USA" 1854 "Northstar Technologies" 1853 "Japan Radio Co" 1852 "Navionics" 1851 "RayMarine" 1850 "Seastar Solutions (formerly Teleflex)" 786 "Johnson Matthey Battery Systems" 785 "Fischer Panda GmbH" 784 "CM Automotive Systems, Inc." 783 "Loup Electronics Inc." 782 "AVR bv (formerly AVR bvba)" 781 "Poly-Planar LLC" 780 "AVID Technology Ltd" 779 "RLC Electronic Systems" 778 "Seakeeper Inc." 777 "Ocean Signal Ltd" 776 "HMI Systems LLC" 775 "ZIEHL-ABEGG Automotive GmbH" 774 "Taisho Corporation" 773 "Clarion Corporation of America" 772 "Blink Marine" 771 "Shaw Development, LLC" 770 "MONOSEM" 769 "Trombetta" 768 "Flores Automation, LLC" 767 "Alliance Wireless Technologies Inc." 766 "Epec Oy" 765 "GIGAVAC" 764 "Bednar FMT s.r.o." 763 "AT-Systems BVBA" 762 "ROJ s.r.l." 761 "MITA OLEODINAMICA S.p.A." 760 "Bernecker + Rainer Industrie Elektronik GmbH" 759 "Hydro-Gear" 758 "Banner Engineering Corp." 757 "IMPCO Technologies" 756 "Maschio Gaspardo S.P.A." 755 "Firefly Integrations" 754 "Parker Hannifin Corp., Automation Group" 753 "AIROD Technologies" 752 "Deep Sea Electronics Plc" 751 "Pacific Track" 750 "Joskin SA" 749 "Chart Inc." 748 "ISOTTA" 747 "Agratronix" 746 "SureFire Ag Systems, Inc." 745 "Cidra Corporate Services Inc." 744 "Woosung Engineering Co., Ltd." 743 "Daemyung Elevator Co., Ltd." 742 "EROAD" 741 "Carling Technologies" 740 "e-Traction" 739 "LXNAV d.o.o." 738 "Blue Ink Technologies" 737 "Balluff GmbH" 736 "Terex Aerial Work Platforms - Genie" 735 "AEM Performance Electronics" 734 "REAPsystems" 733 "Intendia S.L." 732 "Gefran S.p.A." 731 "Modine Manufacturing Company" 730 "BERTHOUD AGRICOLE" 729 "Liebherr" 728 "Streumaster (formerly Streumaster / Panien)" 727 "Dhoot Transmission Pvt Ltd." 726 "MIDORI PRECISIONS" 725 "Hitachi Construction Machinery Co., Ltd." 724 "Electronic Applications, Inc." 723 "Jabil Inc." 722 "Contelec AG" 721 "Hypro" 720 "WITZ Corporation" 719 "Cojali S. L." 718 "Micronet Inc" 717 "Yacht Devices Ltd" 716 "Eaton Control & Power Conversion Division (CPCD)" 715 "Autonnic Research Ltd" 714 "Kobashi Kogyo Co., Ltd." 713 "US Hybrid Corporation" 712 "LOR Manufacturing Company Inc." 711 "DAS Co., LTD" 710 "Greentronics Ltd." 709 "Marquardt GmbH" 708 "Lars Thrane A/S" 707 "Rochester Gauges Inc" 706 "Shanghai Diesel Engine Corporation Limited" 705 "SVAB Hydraulik AB" 704 "JL Audio, Inc." 703 "Hydro Tab Marine Engineering" 702 "Weichai Power Co., Ltd." 701 "BigRoad Inc." 700 "K-Tec Earthmovers Inc." 699 "Harman International Industries" 698 "Scorpion Technologies Ltd." 697 "Ålö AB" 696 "DRS Network & Imaging Systems, LLC (DRS Technologies)" 695 "Weldon Technologies" 694 "GasTOPS Ltd." 693 "Agility Fuel Solutions (formerly Agility Fuel Systems)" 692 "Tanhay Corporation" 691 "Digitroll Agricultural Electronics" 690 "LINAK A/S" 689 "Aarcomm Systems Inc" 688 "Rockford Corp" 687 "Flight Systems, Inc." 686 "Taigene Electric Machinery Corp." 685 "ANEDO (formerly ANEDO Ltd.)" 684 "KEB" 683 "Fosen Elektro" 682 "Eckelmann AG" 681 "BEDIA Motorentechnik GmbH & Co. KG" 680 "AMVAC Chemical Corporation" 679 "Cimco Marine AB" 678 "KeepTruckin, Inc." 677 "DSA Daten- und Systemtechnik GmbH" 676 "Danfoss IXA A/S" 675 "Kawasaki Motors Corp., USA" 674 "Yara International ASA" 673 "Caruelle Nicolas" 672 "OPTIMA Concept" 671 "Innovative Controls Inc." 670 "STEMCO LP" 669 "Quantum Fuel Systems Technologies Worldwide, Inc" 668 "MacDon Industries Ltd." 667 "Bartec" 666 "Schaeffler Technologies AG & Co., KG" 665 "Gebr. Bode GmbH & Co. KG" 664 "Level Developments Ltd" 663 "Delta Systems, Inc" 662 "Kissling Elektrotechnik GmbH" 661 "SPAL Automotive S.r.l." 660 "Auto-Gaz Centrum" 659 "Data Panel Corp." 658 "Shenzhen Jiuzhou Himunication Technology Co., Ltd" 657 "Terzo Power Systems" 656 "PRO SOLUS do Brasil" 655 "Genge & Thoma AG" 654 "Kohler Power Systems, Detroit Engine Development Center (DEDC)" 653 "AEV, spol. s r. o." 652 "MicroControl GmbH & Co. KG" 651 "Takakita Co, Ltd." 650 "Seiko Epson Corp." 649 "Control-Q B.V." 648 "OJSC Ekran" 647 "Siloking" 646 "Veenhuis Machines B.V." 645 "esd electronic system design gmbh" 644 "KUS USA" 643 "Bogballe A/S" 642 "Moog / Aspen Motion Technologies" 641 "Diverse Yacht Services" 640 "Power Solutions International" 639 "Startec s.r.l." 638 "KVH Industries, Inc." 637 "Bavaria Yachtbau GmbH" 636 "Divelbiss Corporation" 635 "Argo Tractors S.p.A." 634 "Rocky Research" 633 "TORC Robotics" 632 "Pepperl+Fuchs GmbH" 631 "Reltima" 630 "SmartDrive Systems Inc." 629 "Agri Info Design, Ltd." 524 "Vomax Instrumentation Pty. Ltd." 523 "Reggio Emilia Innovazione" 522 "Nebraska Tractor Test Laboratory" 521 "Clever Devices Ltd." 520 "Trapeze" 519 "Peeters Landbouwmachines b.v." 518 "Transas USA Inc." 517 "Noland Engineering" 516 "AVAT Automation GmbH" 515 "GINAF Trucks Nederland B.V." 514 "DISTek Integration, Inc." 513 "Precision Technology (Formerly FarmscanAg)" 512 "Inpower LLC" 511 "Sulky" 510 "Marinesoft Co. Ltd" 509 "MOTORTECH GmbH" 508 "Transtech Innovations" 507 "ISOBUS Test Center" 506 "IHI STAR Machinery Corporation" 505 "Yetter Farm Equipment" 504 "Vesper Marine" 503 "Naviop S.R.L." 502 "Attwood Corporation" 501 "Agrotronix S.A." 500 "Oxbo International Corporation" 499 "LCJ Capteurs" 498 "Innovative Design Solutions, Inc." 497 "SENTRON Sistemas Embarcados" 496 "W. Gessmann GmbH" 495 "HOLMER Maschinenbau GmbH" 494 "Synerject" 493 "Watcheye" 492 "Inergy Automotive Systems" 491 "Penny and Giles Ltd" 490 "QuikQ" 489 "Appareo Systems, LLC" 488 "The Charles Machine Works, Inc." 487 "DSE Test Solutions A/S" 486 "Westport Innovations Inc." 485 "MATT automotive" 484 "Headsight Inc." 483 "Valeo" 482 "Tricon Electronics" 481 "Chetco Digital Instruments" 480 "EnerDel, Inc." 479 "Vapor Bus International" 478 "OceanSat B.V." 477 "OilQuick AB" 476 "Hummingbird Marine Electronics" 475 "GME" 474 "Persen Technologies Inc." 473 "Boss Industries, Inc." 472 "Tenneco Inc." 471 "Sea Cross Marine AB" 628 "Falck Schmidt Defence Systems" 627 "Radio Ocean" 626 "AVL DiTEST GmbH" 625 "Global MRV Inc." 624 "Blackbox Machine Control Pty Ltd" 623 "Xirgo Technologies" 622 "Floyd Bell Inc" 621 "Hagie Manufacturing Company" 620 "Sevcon Ltd." 619 "Right Weigh Load Scales" 618 "Evrard SA" 617 "Zero Emission Vehicles" 616 "SMART-TEC s.r.o." 615 "Networkfleet, Verizon Telematics" 614 "ARLT Technologies GmbH" 613 "HKS Co., Ltd." 612 "Samwon IT" 611 "Esterline" 610 "Trail Tech" 609 "Walvoil S.p.A." 608 "Gale Banks Engineering" 607 "Knappco/Civacon" 606 "Intellian Technologies" 605 "Aventics GmbH" 604 "Indexator Rototilt Systems AB" 603 "Kereval" 602 "Nomad Digital Ltd." 601 "Navitas Systems" 600 "Aquatic AV" 599 "Spudnik Equipment Co, LLC" 598 "ABB Turbo Systems Ltd" 597 "Hydac Filter Systems GmbH" 596 "Brunelco Electronic Innovators B.V." 595 "CustomWare" 594 "Kongsberg Automotive" 593 "Sensata Technologies" 592 "tecsis GmbH" 591 "United States Coast Guard" 590 "ARGO-HYTOS GMBH" 589 "MICO, Inc." 588 "Vignal Systems" 587 "JCA Electronics" 586 "Suzuki Motor Corp" 585 "Industrial Electronic Controls" 584 "CarMedialab GmbH" 583 "Yachtcontrol" 582 "Innovative Software Engineering" 581 "Väderstad - Verken AB" 580 "San Jose Technology, Inc." 579 "KVH Industries, Inc." 578 "advanSea" 577 "Denchi Power Ltd  (formerly ABSL Power Solutions Limited)" 576 "Vectia" 575 "Lytx" 574 "Vishay Precision Group" 573 "Orolia Ltd" 572 "Fasse Valves" 571 "Marinecraft Co., Ltd." 570 "frenzel + berg electronic GmbH & Co. KG" 569 "LORD MicroStrain Sensing Systems" 568 "Makersan Ltd. Co." 567 "Lithiumstart LLC" 566 "Geode Technology, Inc." 565 "Micro-Trak Systems, Inc." 564 "Auto Power Electronic" 563 "LOHR Sistemas Eletronicos LTDA" 562 "Bombardier Transportation GmbH" 561 "b-plus GmbH" 560 "Iowa State University, Agricultural and Biosystems Engineering" 559 "Four Peaks Navigation" 558 "Davis Instruments Corp." 557 "Rockson Automation GmbH" 556 "Doosan Infracore Norway" 555 "Sasaki Corporation" 554 "iris-GmbH infrared & intelligent sensors" 553 "KIB Electronics" 552 "Matsuyama Plow Mfg Co, Ltd" 551 "Wexler CSD Ltd." 550 "SUN-A Corporation" 549 "ROAD Deutschland GmbH" 548 "TM4 Inc." 547 "Thomson Linear LLC" 546 "Maruyama Mfg Co, Inc." 545 "GS Hydraulics" 544 "Au Group Electronics" 543 "BAUER Maschinen GmbH" 542 "Dinamica Generale s.p.a." 541 "Total Fire Systems, Inc." 540 "Dinex A/S" 539 "Mobileview" 538 "Crop Ventures, Inc." 537 "Schrader Electronics Ltd." 536 "SSI Technologies" 535 "MOTORPAL, a.s." 534 "Webasto Thermo & Comfort SE" 533 "Doran Manufacturing, LLC" 532 "Onwa Marine Electronics Co Ltd." 531 "Genge & Thoma AG" 530 "NMEA" 529 "National Instruments Korea" 528 "Hoganas AB, Electric Drive Systems" 527 "GKN Walterscheid GmbH" 526 "LOFA Industries, Inc" 525 "Rust Sales INC" 470 "SI-TEX Marine Electronics" 469 "RA Consulting GmbH" 468 "Tyco Fire Protection Products" 467 "Lely Industries N.V." 466 "Veethree Electronics and Marine LLC" 465 "Ashcroft Inc" 464 "Leach International Corporation" 463 "PROBOTIQ" 462 "IHI Shibaura Machinery Corporation" 461 "HAWE Hydraulik SE" 460 "San Giorgio S.E.I.N." 459 "Alltek Marine Electronics Corp" 458 "Control Solutions, Inc." 457 "RUSELPROM-ElectricDrive Ltd" 456 "General Kinetics" 455 "ADZ NAGANO GmbH" 454 "NGK Spark Plug Co. Ltd" 453 "Cooper Bussmann" 452 "WIKA Alexander Wiegand SE & Co. KG" 451 "Parker Hannifin Corp" 450 "Dycor Technologies Ltd." 449 "Polaris Industries Inc" 448 "Stanadyne Corporation, Electronics Systems" 447 "Great Plains Mfg." 446 "CertTech, L.L.C." 445 "KAT MECHATRONIC, Electronic Product Division" 444 "ITT Power Solutions" 443 "SignalQuest, Inc." 442 "Horsch Maschinen GmbH" 441 "PTG Reifendruckregelsysteme GmbH" 440 "Cummins Power Generation" 439 "Hyundai Heavy Industries" 438 "Comar Systems Ltd" 437 "Digital Yacht Limited" 436 "Kinze Manufacturing" 435 "Zunhammer GmbH" 434 "Stored Energy Systems" 433 "Rowe Electronics" 432 "S&A Systems, Inc." 431 "Tohatsu Corporation" 430 "Auteq Telematica S.A." 429 "Rota Engineering Ltd." 425 "Methode Electronics Inc, MDI" 424 "Odyne LLC" 423 "BSM Wireless, Inc." 422 "True Heading AB" 421 "Vertex Standard Co, Ltd" 420 "Vermeer Corporation, ACS Group" 419 "Fusion Electronics Ltd" 418 "Intellistick Inc" 417 "KZValve" 416 "Kubota Corporation" 415 "Valid Manufacturing Ltd." 414 "Cattron Group International" 413 "Datapross Nijbroek bv" 412 "WebTech Wireless Inc." 411 "Hy-Drive Technologies Ltd." 410 "COBO S.p.A. Divisione 3B6" 409 "Transfluid S.r.L." 408 "Corvus Energy Ltd." 407 "Comtech Mobile Datacom" 406 "Vecima Networks Inc." 405 "Wema System AS" 404 "Com Nav Marine Ltd" 403 "Trackwell ADS, Inc." 402 "Simma Software, Inc." 401 "Torqeedo GmbH" 400 "Livorsi Marine" 399 "ISEKI & Co., Ltd." 398 "Hilite International" 397 "Sanyo-kiki Co Ltd." 396 "Beyond Measure" 395 "GENTEC S.R.L." 394 "Capi 2 Nederland B.V." 393 "Harvest Tec, Inc" 392 "Tianyuan Technology Co Ltd." 391 "Electronic Design for Industry, Inc" 390 "Partech Inc." 389 "Benchmark Electronics, Minnesota Division" 388 "Innomatix, LLC" 387 "Orscheln Products, LLC" 386 "JLG Automation BVBA" 385 "Johnson Outdoor Marine Electronics" 384 "Camano Light" 383 "MCL Industries" 382 "National Agriculture and Food Research Organization" 381 "B & G" 380 "Suntech International Ltd." 379 "Yamabiko Corporation" 378 "Glendinning Marine Products" 377 "ifm electronic gmbh" 376 "Quake Global" 375 "Williams Controls Inc." 374 "Northern Lights, Inc." 373 "Electronic Design Inc." 372 "Delphi" 371 "Heinzmann GmbH & Co. KG" 370 "Rolls-Royce Marine AS" 369 "Power Torque Engineering Ltd" 368 "HANSENHOF_electronic" 367 "Fliegl Agrartechnik" 366 "Viewnyx Corp." 365 "Digi-Star, LLC" 364 "OEM Controls Inc." 363 "BEI Duncan" 362 "Poettinger Landtechnik GmbH (formerly Alois Poettinger Maschinenfabrik GmbH)" 361 "InMach" 360 "HJS Emission Technology GmbH & Co KG   (formerly HJS Fahrzeugtechnik GmbH & Co KG)" 359 "Ludwig Bergmann GmbH" 358 "Victron Energy B.V." 357 "Hardi International A/S" 356 "Fischer Panda Generators, Inc" 355 "Mastervolt International B.V." 354 "Junkkari OY" 353 "Hegemon Electronics, Inc." 352 "SAME DEUTZ-FAHR GROUP S.p.A." 351 "Thrane & Thrane" 350 "Noris Marine Systems GmbH & Co KG" 349 "Suonentieto" 348 "Amazonen Werke H. Dreyer" 347 "Honeywell" 346 "Control Solutions" 345 "Korean Maritime University" 344 "Parvus Corporation" 343 "Baumer Group" 342 "THOMAS MAGNETE GmbH" 341 "Boning GmbH & Co" 340 "Continental AG" 339 "Competence Center ISOBUS e.V." 338 "GRAF-SYTECO" 337 "Carraro S.p.A." 336 "APE s.r.o." 335 "Evo Electric Ltd" 334 "Takata-Petri AG" 333 "Hadley Products Corporation" 332 "HWH Corporation" 331 "Horton, Inc." 330 "Kidde Aerospace and Defense" 329 "Deif A/S" 328 "Qwerty Electronik AB" 327 "Sonceboz SA" 326 "Akron Brass Company" 325 "ASM Automation Sensorik Messtechnik GmbH" 324 "Snap-on Diagnostics" 323 "Mobileye Vision Technologies Ltd." 322 "MICHENKA s.r.o." 321 "Ultra Electronics, Electrics" 320 "Miedema Landbouwwerktuigenfabriek B.V." 319 "Cadec Global" 318 "SAT Plan" 317 "Navtronics Bvba" 263 "IMMI" 262 "HydraForce, Inc" 261 "Red Dot Corporation" 260 "Reichhardt GmbH Steuerungstechnik" 259 "Jetter AG" 258 "ARAG" 257 "Honda Motor Co., Ltd" 256 "Tyco Electronics AMP" 255 "MEAS France" 254 "GE Sensing" 253 "Mobile Control Systems" 252 "Sensor-Technik Wiedemann GmbH" 251 "German Agricultural Society, Test Center (DLG)" 250 "Kuhn Group" 249 "Schaltbau GmbH" 248 "Cooper Standard Automotive Active Systems Group" 247 "ePULSE" 246 "Class 1, Inc" 245 "Capstan Ag Systems, Inc." 244 "Techno-Matic" 243 "eRide, Inc." 242 "Kokusandenki Co. Ltd" 241 "Schneider Automation SAS" 240 "Vanair Mfg" 239 "May & Scofield Ltd" 238 "ZF Friedrichshafen AG" 237 "Agtron Enterprises Inc" 236 "NORAC Systems International Inc" 235 "SailorMade Marine Telemetry - Tetra Technology Ltd." 234 "Mondial electronic GmbH" 233 "Yacht Monitoring Solutions Inc." 232 "TSD Integrated Controls" 231 "Topcon Positioning Systems, Inc." 230 "Saucon Technologies" 229 "Garmin International Inc." 228 "Unused (formerly ZF Marine Electronics)" 227 "Lykketronic A/S" 226 "Monaco Coach Corporation" 225 "SKF" 224 "EMMI Network, S.L." 223 "Vaueo Retarder Co., Ltd." 222 "Generac Power Systems, Inc." 221 "SiE" 220 "Beede Electrical Instrument Company, Inc" 219 "Cat OEM Solutions" 218 "Gits Manufacturing Company" 217 "RM Michaelides Software & Elektronik GmbH" 216 "Paneltronics Inc." 215 "Aetna Engineering/Fireboy-Xintex" 214 "MC elettronica Srl" 164 "MTU Friedrichshafen GmbH (formerly DaimlerChrysler Off-Highway)" 163 "BRP Inc." 162 "Axiomatic Technologies" 161 "Offshore Systems (UK) Ltd" 160 "Nido" 159 "NTech Industries Inc" 158 "Firestone Industrial Products Company" 157 "ISSPRO Inc." 156 "ITT Industries - Cannon" 155 "Vetronix Corporation" 154 "Westerbeke Corporation" 153 "Woodward, Industrial Controls Division" 152 "elobau GmbH & Co. KG" 151 "Raven Industries, Inc." 150 "Fleetguard" 149 "Holset" 148 "Blue Water Data, Inc." 147 "Nautibus electronic GmbH" 146 "Maxima Technologies" 145 "MurCal Controls" 144 "Mercury Marine" 143 "W. Gmeiner GmbH & Co." 142 "TRW Automotive (Commercial Steering Systems)" 141 "Thales Navigation Ltd." 140 "Lowrance Electronics, Inc." 139 "Caterpillar Trimble Control Technologies (CTCT), LLC" 138 "Georg Fritzmeier GmbH & Co. KG" 137 "Maretron" 136 "Komatsu Ltd" 135 "Airmar Technology Corporation" 134 "Iris Technology Ltd" 133 "Bucher Schoerling GmbH" 132 "Mulag-Fahrzeugwerk" 131 "ITT Industries" 130 "Nido - Universal Machines B.V." 129 "OMNEX Control Systems Inc." 128 "Gerhard Duecker GmbH & Co. KG" 127 "Holland USA" 126 "Driver Tech" 125 "Nevada Automotive Test Center" 124 "Hydac Electronic" 123 "Basler Electric" 122 "FG Wilson (Engineering) Limited" 121 "HED (Hydro Electronic Devices, Inc.)" 120 "RDS Technology Ltd" 119 "IntegriNautics  " 118 "Intron GmbH" 117 "HUSCO International" 116 "BEELINE Technologies" 115 "NACCO Materials Handling Group, Inc." 114 "EControls, Inc." 113 "Stress-Tek, Inc." 112 "MECALAC" 111 "Bernard Krone Holding SE & Co. KG (formerly Maschinenfabrik Bernard Krone GmbH)" 110 "EPIQ Sensor-Nite" 109 "TeeJet Technologies Denmark (formerly LH Technologies ApS)" 108 "WTK-Elecktronik GmbH" 107 "Grimme Landmaschinen GmbH & Co. KG" 106 "BAE Systems Controls, Inc." 105 "Kiepe Elektrik GmbH & Co. KG" 104 "CLAAS KGaA mbH (formerly CLAAS Selbstfahrende Erntemaschinen GmbH)" 103 "CLAAS E-Systems GmbH (formerly CLAAS E-Systems KGaA mbH & Co. KG)" 102 "AGCO (formerly AGCO GmbH & Co.)" 101 "Sensoria" 100 "VDO Technik AG" 99 "International Transmissions Ltd (ITL)" 98 "Mueller-Elektronik GmbH & Co" 97 "Ag Leader Technology, Inc." 96 "Mech@tronic IT GmbH" 95 "Pacific Insight Electronics Corp." 94 "CNH Industrial N.V. (formerly CNH Global N.V.)" 93 "Perkins Engines Company Ltd." 92 "Ag-Chem Equipment Co., Inc." 91 "BSG Bodensee Steuergeraete GmbH" 90 "Knorr-Bremse SfN GmbH" 89 "Kverneland Group, Electronics Division" 88 "Hemisphere GPS Inc (formerly Satloc Precision GPS)" 87 "J.C. Bamford Excavators Ltd (JCB)" 86 "C. E. Niehoff & Company" 85 "Kohler Co" 84 "New Holland UK Limited" 83 "Bendix VORAD Technologies (formerly Eaton VORAD Technologies)" 82 "Bobcat/Ingersoll-Rand (formerly Melroe/Ingersoll-Rand)" 81 "Fire Research Corp." 80 "Twin Disc, Inc." 79 "Daimler Benz AG - Engine Division (PBM)" 78 "Frank W. Murphy Manufacturing, Inc" 77 "Deere Power Systems Group" 76 "unused (formerly Deere & Co, Construction Division)" 75 "Deere & Co, Agricultural Division" 74 "Eaton Axle-Brake Division" 73 "LeTourneau, Inc." 72 "Sisu Corporation" 71 "Vansco Electronics Ltd." 70 "Flex-coil Limited" 69 "Trimble Navigation" 316 "ITT Flow Control" 315 "Icom Incorporated" 314 "CSM GmbH" 313 "Ilmor Engineering, Inc." 312 "Lectronix, Inc." 311 "Patrick Power Products" 310 "TECNORD srl" 309 "Krauss-Maffei Wegmann GmbH & Co. KG" 308 "Cyntrx" 307 "MAS Technologies" 306 "Sleipner Motor AB" 305 "NovAtel Inc" 304 "EmpirBus AB" 303 "CTS Corporation" 302 "Nissin Kogyo Co., LTD" 301 "Parker Hannifin (UK) Ltd FDE group" 300 "Systron Donner Automotive" 299 "Rauch" 298 "Holley Performance" 297 "Zonar Systems Inc" 296 "micro dynamics GmbH" 295 "BEP Marine" 294 "Grayhill Inc." 293 "Spyder Controls Corp." 292 "IKUSI - Angel Iglesias S.A." 291 "Groeneveld Transport Efficiency BV" 290 "Kuebler GmbH" 289 "Watlow" 288 "Mitsubishi FUSO Truck & Bus Corp." 287 "NTech Industries, Inc" 286 "Coelmo srl" 285 "Sea Recovery Corp" 284 "Mobile Tech Chile" 283 "CWF Hamilton & Co Ltd" 282 "Medallion Instrumentation Systems" 281 "Precision Governors LLC" 280 "Leica Geosystems Pty Ltd" 279 "Geometris LP" 278 "Takata Electronics" 277 "LHP Telematics" 276 "Aqua-Hot Heating Systems" 275 "Navico Egersund AS" 274 "LTW Technology Co., LTD" 273 "Active Research Limited" 272 "Gross Mechanical Laboratories, Inc" 271 "Cole Hersee" 270 "Tennant" 269 "Saft America Inc.,  Space & Defense Division" 268 "Accurate Technologies" 267 "Red Lion Controls, Inc" 266 "International Thermal Research Ltd" 265 "MTS Sensor Technologie GmbH" 264 "Autolync" 213 "CNH Belgium N.V." 212 "Sure Power Industries, Inc" 211 "DNA Group" 210 "Iteris, Inc." 209 "Bell Equip. Co. SA (PTY) LTD" 208 "Drew Technologies, Inc" 207 "Otto Engineering" 206 "port GmbH" 205 "SmarTire Systems Inc" 204 "The Morey Corporation" 203 "MILtronik GmbH" 202 "Curtis Instruments, Inc" 201 "Disenos y Tecnologia S.A." 200 "MGM Brakes" 199 "ACTIA Group (formerly Actia Corp)" 198 "Mystic Valley Communications" 197 "Mechron Power Systems" 196 "LEMKEN GmbH & Co KG" 195 "General Engine Products" 194 "TriMark Corporation" 193 "Jeppesen Marine" 192 "Floscan" 191 "XRS Corporation (formerly XATA Corporation)" 190 "Hella KGaA Hueck & Co" 189 "QUALCOMM" 188 "EMP Corp" 187 "Air-Weigh" 186 "Altronic, Inc" 185 "Beede Electrical Instrument Company" 184 "EIA Electronics" 183 "KDS Controls, Inc" 182 "Vehicle Systems Engineering B.V." 181 "Coretronics, Inc." 180 "Smart Power Systems" 179 "TeeJet Technologies Springfield (formerly Midwest Technologies Illinois, LLC)" 178 "Continental Automotive GmbH (formerly Siemens VDO Automotive AG)" 177 "Diagnostic Systems Associates" 176 "Moritz Aerospace" 175 "Veris Technologies, Inc." 174 "AB Volvo Penta" 173 "Ryeso, Inc." 172 "Yanmar Co., Ltd. (formerly Yanmar Marine USA)" 171 "Topcon Electronics GmbH & Co. KG (formerly Wachendorff Elektronik GmbH & Co. KG)" 170 "Computronics Corporation Ltd." 169 "Marlin Technologies Inc." 168 "Xantrex" 167 "JLG Industries Inc" 166 "John Deere Electronic Solutions (formerly Phoenix International)" 165 "CPAC Systems AB" 68 "Scania" 67 "John Deere Coffeyville Works (formerly Funk Manufacturing Company)" 66 "John Deere Construction Equipment Division" 65 "MAN Nutzfahrzeuge AG" 64 "Unused (formerly SpectraPrecision Laserplane, then SpectraPhysics)" 63 "ZF Industries Inc." 62 "Wabco" 61 "Volvo Truck Corp." 60 "Volvo Trucks North America Inc." 59 "VES Inc." 58 "SPX Corporation, OTC Div" 57 "Danfoss  (formerly Sauer Sundstrand Co, then Sauer-Danfoss Co)" 56 "SAIC" 55 "Ryder System Inc." 54 "Meritor Wabco" 53 "Continental Automotive Systems US, Inc. (formerly Rockwell Land Transportation)" 52 "Meritor Automotive, Inc. (formerly Rockwell Automotive)" 51 "Robert Bosch GmbH" 50 "Robert Bosch Corp" 49 "RE America Inc." 48 "Pollak Alphabet" 47 "Phillips Semiconductor" 46 "Noregon Systems, Inc  (formerly Parasoft Computing Solutions)" 45 "PACCAR" 44 "Nippondenso Co. Ltd." 43 "International Truck and Engine Corporation - Vehicle Electronics (formerly Navistar Intl Trans Corp.)" 42 "International Truck and Engine Corporation - Engine Electronics  (formerly Navistar Intl Trans Co., Engine Electronics)" 41 "Motorola Inc." 40 "Motorola AIEG Inc." 39 "Microfirm Inc." 38 "Micro Processor Systems Inc." 37 "Mack Trucks Inc." 36 "Lucas Ind." 35 "Kenworth Truck Co." 34 "Kelsey Hayes Co." 33 "John Deere" 32 "Jacobs Vehicle Systems" 31 "J Pollak Corp" 30 "Isuzu Motors Ltd" 29 "Hino Motors Ltd." 28 "Grote Ind. Inc." 27 "GMC" 26 "General Motors Corp, Service Technology Grp" 25 "Daimler Trucks North America LLC (formerly Freightliner LLC)" 24 "Ford Motor Co., Vehicle Controls" 23 "Ford Motor Co., Heavy Truck" 22 "Ford Motor Co., Electronic Concepts & Systems" 21 "Echlin Inc., Midland Brake Inc." 20 "Eaton Ltd" 19 "Eaton Corp. Trucking Info Services" 18 "Eaton Corp, Transmission Div." 17 "Eaton Corp, Corp Res & Dev" 16 "Eaton Corp" 15 "DICKEY-john Corporation" 14 "Detroit Diesel Corporation" 13 "Delco Electronics" 12 "Deere & Company, Precision Farming" 11 "Dearborn Group Inc." 10 "Cummins Inc (formerly Cummins Engine Co)" 9 "Chrysler Corp." 8 "Caterpillar Inc." 7 "Case Corp." 6 "Berifors Electronics AB" 5 "AMP Inc." 4 "Ametek-Dixson" 3 "Ametek, US Gauge Division" 2 "Allison Transmission, Inc." 1 "Bendix Commercial Vehicle Systems LLC (formerly Allied Signal Inc.)" 0 "Reserved" ;
VAL_ 2314732286 COGReference 0 "True" 1 "Magnetic" 2 "Error" 3 "Null" ;
VAL_ 2314732286 SID 255 "nVldPsFxTTItTRng0T250FrVldPstnFx" ;
